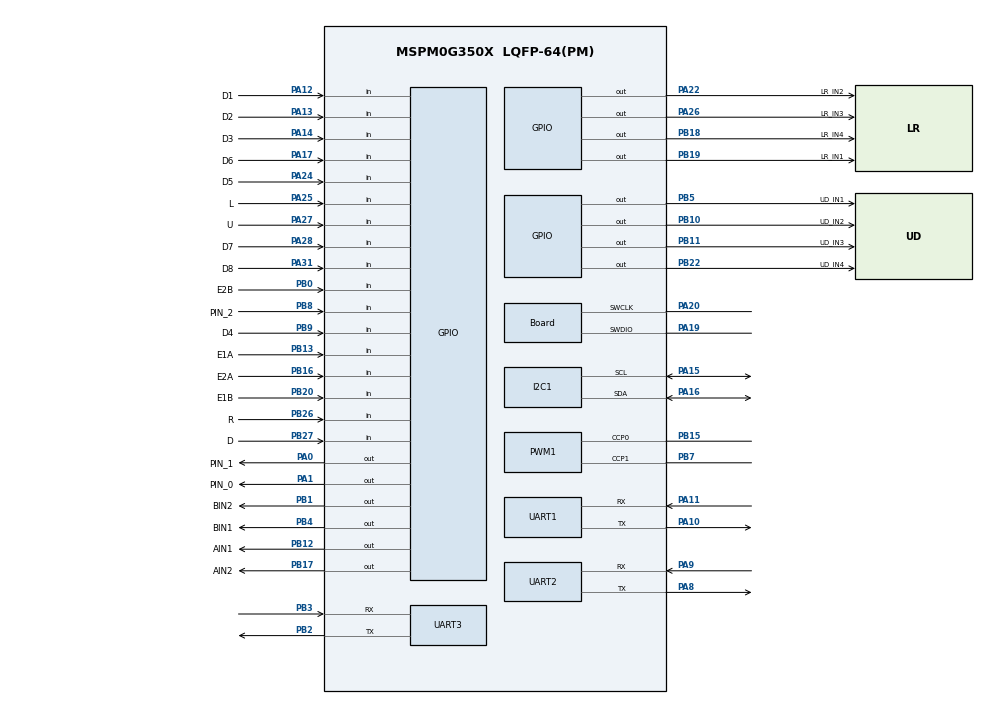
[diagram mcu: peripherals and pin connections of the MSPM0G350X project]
/**
 * @cliArgs --device "MSPM0G350X" --package "LQFP-64(PM)" --part "Default" --product "mspm0_sdk@2.00.01.00"
 * @versions {"tool":"1.20.0+3587"}
 */

/**
 * Import the modules used in this configuration.
 */
const Board         = scripting.addModule("/ti/driverlib/Board");
const GPIO          = scripting.addModule("/ti/driverlib/GPIO", {}, false);
const GPIO1         = GPIO.addInstance();
const GPIO2         = GPIO.addInstance();
const GPIO3         = GPIO.addInstance();
const GPIO4         = GPIO.addInstance();
const GPIO5         = GPIO.addInstance();
const GPIO6         = GPIO.addInstance();
const GPIO7         = GPIO.addInstance();
const GPIO8         = GPIO.addInstance();
const I2C           = scripting.addModule("/ti/driverlib/I2C", {}, false);
const I2C1          = I2C.addInstance();
const PWM           = scripting.addModule("/ti/driverlib/PWM", {}, false);
const PWM1          = PWM.addInstance();
const SYSTICK       = scripting.addModule("/ti/driverlib/SYSTICK");
const TIMER         = scripting.addModule("/ti/driverlib/TIMER", {}, false);
const TIMER1        = TIMER.addInstance();
const UART          = scripting.addModule("/ti/driverlib/UART", {}, false);
const UART1         = UART.addInstance();
const UART2         = UART.addInstance();
const UART3         = UART.addInstance();
const ProjectConfig = scripting.addModule("/ti/project_config/ProjectConfig");

/**
 * Write custom configuration values to the imported modules.
 */
Board.peripheral.$assign          = "DEBUGSS";
Board.peripheral.swclkPin.$assign = "PA20";
Board.peripheral.swdioPin.$assign = "PA19";

GPIO1.$name                         = "GPIO_sda";
GPIO1.associatedPins[0].$name       = "PIN_0";
GPIO1.associatedPins[0].ioStructure = "OD";
GPIO1.associatedPins[0].pin.$assign = "PA1";

GPIO2.$name                         = "GPIO_scl";
GPIO2.associatedPins[0].$name       = "PIN_1";
GPIO2.associatedPins[0].ioStructure = "OD";
GPIO2.associatedPins[0].pin.$assign = "PA0";

GPIO3.$name                         = "motor";
GPIO3.associatedPins.create(8);
GPIO3.associatedPins[0].$name       = "AIN1";
GPIO3.associatedPins[0].pin.$assign = "PB12";
GPIO3.associatedPins[1].$name       = "AIN2";
GPIO3.associatedPins[1].pin.$assign = "PB17";
GPIO3.associatedPins[2].$name       = "BIN1";
GPIO3.associatedPins[2].pin.$assign = "PB4";
GPIO3.associatedPins[3].$name       = "BIN2";
GPIO3.associatedPins[3].pin.$assign = "PB1";
GPIO3.associatedPins[4].$name       = "E2A";
GPIO3.associatedPins[4].direction   = "INPUT";
GPIO3.associatedPins[4].interruptEn = true;
GPIO3.associatedPins[4].polarity    = "RISE";
GPIO3.associatedPins[4].pin.$assign = "PB16";
GPIO3.associatedPins[5].$name       = "E2B";
GPIO3.associatedPins[5].direction   = "INPUT";
GPIO3.associatedPins[5].polarity    = "RISE";
GPIO3.associatedPins[5].pin.$assign = "PB0";
GPIO3.associatedPins[6].$name       = "E1A";
GPIO3.associatedPins[6].direction   = "INPUT";
GPIO3.associatedPins[6].interruptEn = true;
GPIO3.associatedPins[6].polarity    = "RISE";
GPIO3.associatedPins[6].pin.$assign = "PB13";
GPIO3.associatedPins[7].$name       = "E1B";
GPIO3.associatedPins[7].direction   = "INPUT";
GPIO3.associatedPins[7].polarity    = "RISE";
GPIO3.associatedPins[7].pin.$assign = "PB20";

GPIO4.$name                              = "GRAY";
GPIO4.associatedPins.create(8);
GPIO4.associatedPins[0].direction        = "INPUT";
GPIO4.associatedPins[0].internalResistor = "PULL_UP";
GPIO4.associatedPins[0].$name            = "D1";
GPIO4.associatedPins[0].pin.$assign      = "PA12";
GPIO4.associatedPins[1].$name            = "D2";
GPIO4.associatedPins[1].direction        = "INPUT";
GPIO4.associatedPins[1].internalResistor = "PULL_UP";
GPIO4.associatedPins[1].pin.$assign      = "PA13";
GPIO4.associatedPins[2].$name            = "D3";
GPIO4.associatedPins[2].direction        = "INPUT";
GPIO4.associatedPins[2].internalResistor = "PULL_UP";
GPIO4.associatedPins[2].pin.$assign      = "PA14";
GPIO4.associatedPins[3].$name            = "D4";
GPIO4.associatedPins[3].internalResistor = "PULL_UP";
GPIO4.associatedPins[3].direction        = "INPUT";
GPIO4.associatedPins[3].pin.$assign      = "PB9";
GPIO4.associatedPins[4].$name            = "D5";
GPIO4.associatedPins[4].direction        = "INPUT";
GPIO4.associatedPins[4].internalResistor = "PULL_UP";
GPIO4.associatedPins[4].pin.$assign      = "PA24";
GPIO4.associatedPins[5].$name            = "D6";
GPIO4.associatedPins[5].direction        = "INPUT";
GPIO4.associatedPins[5].internalResistor = "PULL_UP";
GPIO4.associatedPins[5].pin.$assign      = "PA17";
GPIO4.associatedPins[6].$name            = "D7";
GPIO4.associatedPins[6].direction        = "INPUT";
GPIO4.associatedPins[6].internalResistor = "PULL_UP";
GPIO4.associatedPins[6].pin.$assign      = "PA28";
GPIO4.associatedPins[7].$name            = "D8";
GPIO4.associatedPins[7].direction        = "INPUT";
GPIO4.associatedPins[7].internalResistor = "PULL_UP";
GPIO4.associatedPins[7].pin.$assign      = "PA31";

GPIO5.$name                              = "far_red";
GPIO5.associatedPins[0].$name            = "PIN_2";
GPIO5.associatedPins[0].direction        = "INPUT";
GPIO5.associatedPins[0].internalResistor = "PULL_DOWN";
GPIO5.associatedPins[0].pin.$assign      = "PB8";

GPIO6.$name                         = "STEP_MOTOR_LR";
GPIO6.associatedPins.create(4);
GPIO6.associatedPins[0].$name       = "LR_IN1";
GPIO6.associatedPins[0].pin.$assign = "PB19";
GPIO6.associatedPins[1].$name       = "LR_IN2";
GPIO6.associatedPins[1].pin.$assign = "PA22";
GPIO6.associatedPins[2].$name       = "LR_IN3";
GPIO6.associatedPins[2].pin.$assign = "PA26";
GPIO6.associatedPins[3].$name       = "LR_IN4";
GPIO6.associatedPins[3].pin.$assign = "PB18";

GPIO7.$name                         = "STEP_MOTOR_UD";
GPIO7.associatedPins.create(4);
GPIO7.associatedPins[0].$name       = "UD_IN1";
GPIO7.associatedPins[0].pin.$assign = "PB5";
GPIO7.associatedPins[1].$name       = "UD_IN2";
GPIO7.associatedPins[1].pin.$assign = "PB10";
GPIO7.associatedPins[2].$name       = "UD_IN3";
GPIO7.associatedPins[2].pin.$assign = "PB11";
GPIO7.associatedPins[3].$name       = "UD_IN4";
GPIO7.associatedPins[3].pin.$assign = "PB22";

GPIO8.$name                              = "STEP_KEY";
GPIO8.associatedPins.create(4);
GPIO8.associatedPins[0].$name            = "L";
GPIO8.associatedPins[0].direction        = "INPUT";
GPIO8.associatedPins[0].internalResistor = "PULL_UP";
GPIO8.associatedPins[0].pin.$assign      = "PA25";
GPIO8.associatedPins[1].$name            = "R";
GPIO8.associatedPins[1].direction        = "INPUT";
GPIO8.associatedPins[1].internalResistor = "PULL_UP";
GPIO8.associatedPins[1].pin.$assign      = "PB26";
GPIO8.associatedPins[2].$name            = "U";
GPIO8.associatedPins[2].direction        = "INPUT";
GPIO8.associatedPins[2].internalResistor = "PULL_UP";
GPIO8.associatedPins[2].pin.$assign      = "PA27";
GPIO8.associatedPins[3].$name            = "D";
GPIO8.associatedPins[3].direction        = "INPUT";
GPIO8.associatedPins[3].internalResistor = "PULL_UP";
GPIO8.associatedPins[3].pin.$assign      = "PB27";

I2C1.$name                             = "I2C_OLED";
I2C1.basicEnableController             = true;
I2C1.basicControllerStandardBusSpeed   = "Fast";
I2C1.peripheral.$assign                = "I2C1";
I2C1.peripheral.sdaPin.$assign         = "PA16";
I2C1.peripheral.sclPin.$assign         = "PA15";
I2C1.sdaPinConfig.$name                = "ti_driverlib_gpio_GPIOPinGeneric0";
I2C1.sdaPinConfig.hideOutputInversion  = scripting.forceWrite(false);
I2C1.sdaPinConfig.onlyInternalResistor = scripting.forceWrite(false);
I2C1.sdaPinConfig.passedPeripheralType = scripting.forceWrite("Digital");
I2C1.sclPinConfig.$name                = "ti_driverlib_gpio_GPIOPinGeneric1";
I2C1.sclPinConfig.hideOutputInversion  = scripting.forceWrite(false);
I2C1.sclPinConfig.onlyInternalResistor = scripting.forceWrite(false);
I2C1.sclPinConfig.passedPeripheralType = scripting.forceWrite("Digital");

PWM1.$name                              = "PWM_motor";
PWM1.pwmMode                            = "EDGE_ALIGN_UP";
PWM1.timerCount                         = 32000;
PWM1.peripheral.$assign                 = "TIMG8";
PWM1.peripheral.ccp0Pin.$assign         = "PB15";
PWM1.peripheral.ccp1Pin.$assign         = "PB7";
PWM1.PWM_CHANNEL_0.$name                = "ti_driverlib_pwm_PWMTimerCC0";
PWM1.PWM_CHANNEL_1.$name                = "ti_driverlib_pwm_PWMTimerCC1";
PWM1.ccp0PinConfig.direction            = scripting.forceWrite("OUTPUT");
PWM1.ccp0PinConfig.hideOutputInversion  = scripting.forceWrite(false);
PWM1.ccp0PinConfig.onlyInternalResistor = scripting.forceWrite(false);
PWM1.ccp0PinConfig.passedPeripheralType = scripting.forceWrite("Digital");
PWM1.ccp0PinConfig.$name                = "ti_driverlib_gpio_GPIOPinGeneric8";
PWM1.ccp0PinConfig.enableConfig         = true;
PWM1.ccp1PinConfig.direction            = scripting.forceWrite("OUTPUT");
PWM1.ccp1PinConfig.hideOutputInversion  = scripting.forceWrite(false);
PWM1.ccp1PinConfig.onlyInternalResistor = scripting.forceWrite(false);
PWM1.ccp1PinConfig.passedPeripheralType = scripting.forceWrite("Digital");
PWM1.ccp1PinConfig.$name                = "ti_driverlib_gpio_GPIOPinGeneric9";

const SYSCTL              = scripting.addModule("/ti/driverlib/SYSCTL", {}, false);
SYSCTL.peripheral.$assign = "SYSCTL";

TIMER1.$name              = "TIMER_0";
TIMER1.timerClkDiv        = 8;
TIMER1.timerClkPrescale   = 100;
TIMER1.timerMode          = "PERIODIC";
TIMER1.timerStartTimer    = true;
TIMER1.interrupts         = ["ZERO"];
TIMER1.timerPeriod        = "6ms";
TIMER1.peripheral.$assign = "TIMG0";

UART1.$name                    = "UART_0";
UART1.targetBaudRate           = 115200;
UART1.enabledInterrupts        = ["RX"];
UART1.peripheral.$assign       = "UART0";
UART1.peripheral.rxPin.$assign = "PA11";
UART1.peripheral.txPin.$assign = "PA10";
UART1.txPinConfig.$name        = "ti_driverlib_gpio_GPIOPinGeneric4";
UART1.rxPinConfig.$name        = "ti_driverlib_gpio_GPIOPinGeneric5";

UART2.$name                    = "UART_1";
UART2.rxFifoThreshold          = "DL_UART_RX_FIFO_LEVEL_ONE_ENTRY";
UART2.enableDMARX              = false;
UART2.enableDMATX              = false;
UART2.enabledInterrupts        = ["RX"];
UART2.targetBaudRate           = 115200;
UART2.peripheral.$assign       = "UART1";
UART2.peripheral.rxPin.$assign = "PA9";
UART2.peripheral.txPin.$assign = "PA8";
UART2.txPinConfig.$name        = "ti_driverlib_gpio_GPIOPinGeneric2";
UART2.rxPinConfig.$name        = "ti_driverlib_gpio_GPIOPinGeneric3";

UART3.$name                    = "UART_2";
UART3.peripheral.$assign       = "UART3";
UART3.peripheral.rxPin.$assign = "PB3";
UART3.peripheral.txPin.$assign = "PB2";
UART3.txPinConfig.$name        = "ti_driverlib_gpio_GPIOPinGeneric6";
UART3.rxPinConfig.$name        = "ti_driverlib_gpio_GPIOPinGeneric7";

ProjectConfig.deviceSpin = "MSPM0G3507";
